AUTOSAR XML (schema 00051)
standard types defined: uint16, uint32
package /Components
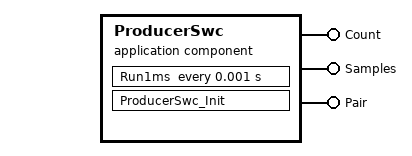
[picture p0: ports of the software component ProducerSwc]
  application sw component type ProducerSwc
    provide port Count: nonqueued-sender-com-spec{data-element=Count, init-value=0}, provided-interface=Count
    provide port Samples: nonqueued-sender-com-spec{data-element=Samples, init-value=[0, 0, 0]}, provided-interface=Samples
    provide port Pair: nonqueued-sender-com-spec{data-element=Pair, init-value=fields=[0, 0]}, provided-interface=Pair
    behavior ProducerSwc_IB: handle-termination-and-restart=NO-SUPPORT
      timing event Event_Run1ms: start-on-event=Run1ms, period=0.001
      runnable ProducerSwc_Init
        data-write-access:
          access IWrite_Count_Count: accessed-variable=Count.Count
      runnable Run1ms
        data-write-access:
          access IWrite_Count_Count: accessed-variable=Count.Count
          access IWrite_Samples_Samples: accessed-variable=Samples.Samples
          access IWrite_Pair_Pair: accessed-variable=Pair.Pair
package /Interfaces
  sender receiver interface Count
    data Count: type=uint32
  sender receiver interface Samples
    data Samples: type=ImpSamples
  sender receiver interface Pair
    data Pair: type=ImpPair
package /DataTypes
  impl type ImpSamples: category=ARRAY
    element ImpSamples: array-size=3, array-size-semantics=FIXED-SIZE, implementation-data-type=uint16
  impl type ImpPair: category=STRUCTURE
    element A: implementation-data-type=uint32
    element B: implementation-data-type=uint32
